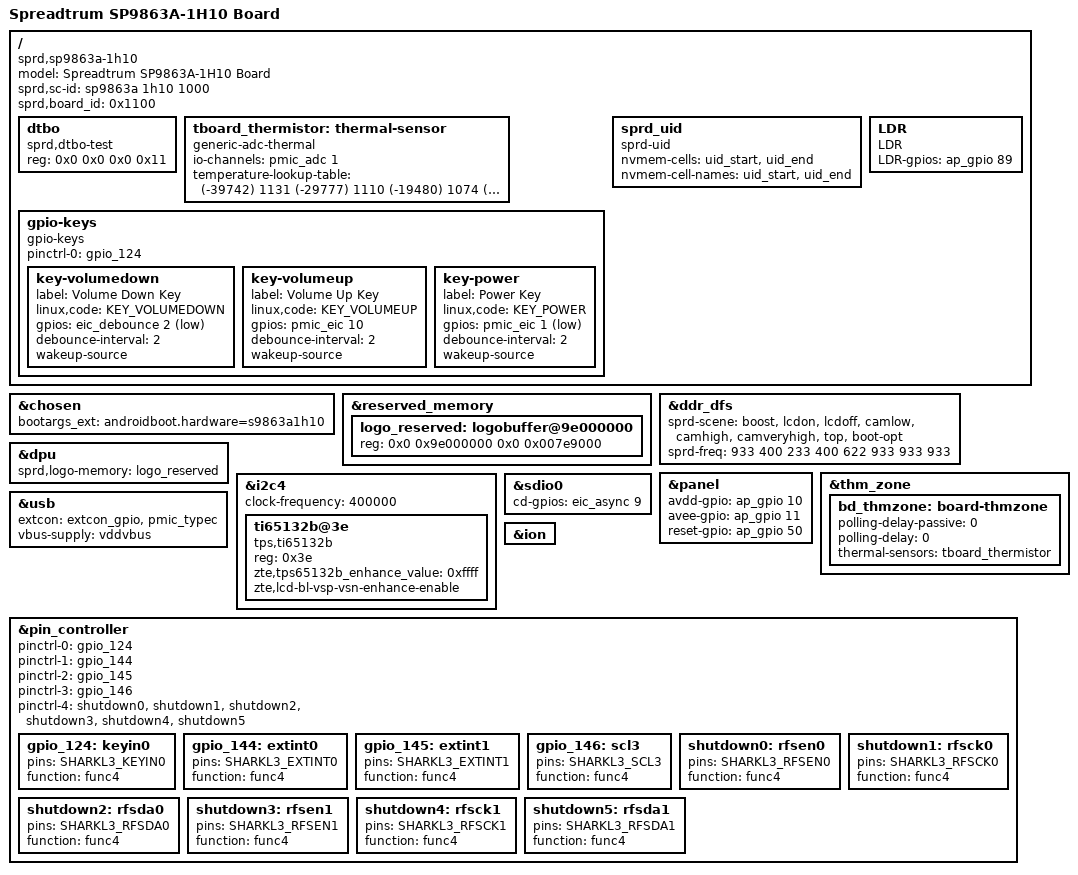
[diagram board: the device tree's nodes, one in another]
/dts-v1/;
/plugin/;
#include <dt-bindings/input/input.h>
#include <dt-bindings/gpio/gpio.h>
#include <dt-bindings/clock/sprd,sc9863a-clk.h>
/*
#include "zte_lcd_easyquick_gc7202_huike_6p5_hd.dtsi"
#include "zte_lcd_easyquick_icnl9911c2_boe_6p5_hd.dtsi"
#include "zte_lcd_easyquick_icnl9911c2_huike_6p5_hd.dtsi"
#include "zte_lcd_easyquick_st7123_huike_6p5_hd.dtsi"
#include "zte_lcd_skyworth_gc7202_panda_6p5_hd.dtsi"
#include "zte_lcd_tongxingda_icnl9911c2_huajiacai_6p5_hd.dtsi"
*/
#include "lcd_icnl9916_qc_hx_mipi_hdp.dtsi"
#include "lcd_ft8057s_cw_mipi_hdp.dtsi"
#include "../lcd/lcd_dummy_mipi.dtsi"

#include "zte_lcd.dtsi"
/*#include <dt-bindings/wdv/wdv.h>*/

/ {
	model = "Spreadtrum SP9863A-1H10 Board";

	compatible = "sprd,sp9863a-1h10", "sprd,sc9863a";

	sprd,sc-id = "sp9863a 1h10 1000";

	sprd,board_id = <0x1100>; //XX00:base board,XX00~XXFF:customize board

	fragment {
		target-path = "/";
		__overlay__ {
			#address-cells = <2>;
			#size-cells = <2>;
			dtbo: dtbo {
				compatible = "sprd,dtbo-test";
				reg = <0x0 0x0 0x0 0x11>;
			};

			tboard_thermistor:thermal-sensor {
				compatible = "generic-adc-thermal";
				#thermal-sensor-cells = <0>;
				io-channels = <&pmic_adc 1>;
				io-channel-names = "sensor-channel";
				temperature-lookup-table = < (-39742) 1131
							(-29777) 1110
							(-19480) 1074
							(-4679) 983
							10110 838
							24805 654
							44922 413
							54903 316
							64895 238
							74884 178
							84883 133
							94883 100
							104880 75
							114889 57
							124872 43 >;
			};

			gpio-keys {
				compatible = "gpio-keys";
				pinctrl-names = "gpio_124";
				pinctrl-0 = <&gpio_124>;
				key-volumedown {
					label = "Volume Down Key";
					linux,code = <KEY_VOLUMEDOWN>;
					gpios = <&eic_debounce 2 GPIO_ACTIVE_LOW>;
					debounce-interval = <2>;
					wakeup-source;
				};
				key-volumeup {
					label = "Volume Up Key";
					linux,code = <KEY_VOLUMEUP>;
					gpios = <&pmic_eic 10 GPIO_ACTIVE_HIGH>;
					debounce-interval = <2>;
					wakeup-source;
				};
				key-power {
					label = "Power Key";
					linux,code =<KEY_POWER>;
					gpios = <&pmic_eic 1 GPIO_ACTIVE_LOW>;
					debounce-interval = <2>;
					wakeup-source;
				};
			};
			sprd_uid {
				compatible = "sprd-uid";
				nvmem-cells = <&uid_start>, <&uid_end>;
				nvmem-cell-names = "uid_start", "uid_end";
			};
			LDR: LDR {
				compatible = "LDR";
				LDR-gpios = <&ap_gpio 89 0>;
			};
		};
	};
};

&chosen {
	bootargs_ext = "androidboot.hardware=s9863a1h10";
};

&reserved_memory {
	#address-cells = <2>;
	#size-cells = <2>;

	logo_reserved: logobuffer@9e000000 {
		reg = <0x0 0x9e000000 0x0 0x007e9000>;
	};

};

&ddr_dfs {
	sprd-scene = "boost", "lcdon", "lcdoff", "camlow",
		"camhigh", "camveryhigh", "top", "boot-opt";
	sprd-freq = <933 400 233 400 622 933 933 933>;
};

&dpu {
	sprd,logo-memory = <&logo_reserved>;
};

&panel {
	avdd-gpio = <&ap_gpio 10 GPIO_ACTIVE_HIGH>;
	avee-gpio = <&ap_gpio 11 GPIO_ACTIVE_HIGH>;
	reset-gpio = <&ap_gpio 50 GPIO_ACTIVE_HIGH>;
};

&thm_zone {
	bd_thmzone: board-thmzone {
		polling-delay-passive = <0>;
		polling-delay = <0>;
		thermal-sensors = <&tboard_thermistor>;
	};
};



&i2c4 {
	#address-cells = <1>;
	#size-cells = <0>;

	status = "okay";
	clock-frequency = <400000>;

	
	/*zte lcd add*/
	ti65132b@3e {
		compatible = "tps,ti65132b";
		reg = <0x3e>;
                /*if set tps65132b_enhance_value,means bigger than this board_id*/
                zte,tps65132b_enhance_value = <0xffff>;
		zte,lcd-bl-vsp-vsn-enhance-enable;
	};	
};

&usb{
	extcon = <&extcon_gpio>, <&pmic_typec>;
	status = "okay";
	vbus-supply = <&vddvbus>;
};

&sdio0 {
	cd-gpios = <&eic_async 9 0>;
};


&ion {
	#address-cells = <1>;
	#size-cells = <0>;

};

&pin_controller {
	pinctrl-names =
	"gpio_124", "gpio_144", "gpio_145", "gpio_146",
	/* Note:If create a new board,need to add the shutdown node */
	"shutdown";
	pinctrl-0 = <&gpio_124>;
	pinctrl-1 = <&gpio_144>;
	pinctrl-2 = <&gpio_145>;
	pinctrl-3 = <&gpio_146>;
	pinctrl-4 = <&shutdown0
			&shutdown1
			&shutdown2
			&shutdown3
			&shutdown4
			&shutdown5>;

	gpio_124: keyin0 {
		pins = "SHARKL3_KEYIN0";
		function = "func4";
	};

	gpio_144: extint0 {
		pins = "SHARKL3_EXTINT0";
		function = "func4";
	};

	gpio_145: extint1 {
		pins = "SHARKL3_EXTINT1";
		function = "func4";
	};

	gpio_146: scl3 {
		pins = "SHARKL3_SCL3";
		function = "func4";
	};

	shutdown0: rfsen0 {
		pins = "SHARKL3_RFSEN0";
		function = "func4";
	};

	shutdown1: rfsck0 {
		pins = "SHARKL3_RFSCK0";
		function = "func4";
	};

	shutdown2: rfsda0 {
		pins = "SHARKL3_RFSDA0";
		function = "func4";
	};

	shutdown3: rfsen1 {
		pins = "SHARKL3_RFSEN1";
		function = "func4";
	};

	shutdown4: rfsck1 {
		pins = "SHARKL3_RFSCK1";
		function = "func4";
	};

	shutdown5: rfsda1 {
		pins = "SHARKL3_RFSDA1";
		function = "func4";
	};
};
